VERSION "HIPBNYYYYYYYYYYYYYYYYYYYYYYYYYYYYYYYYYYYYY/4/%%%/4/'%**4YYY///"

NS_ :

BS_:

BU_:

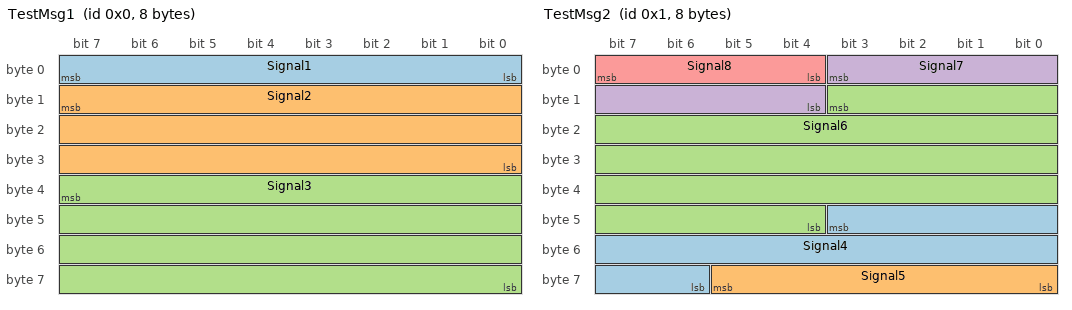
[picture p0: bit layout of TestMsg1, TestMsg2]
BO_ 0 TestMsg1: 8 Vector__XXX
 SG_ Signal1 : 7|8@0- (1,0) [0|0] "" Vector__XXX
 SG_ Signal2 : 15|24@0- (1,0) [0|0] "" Vector__XXX
 SG_ Signal3 : 39|32@0- (1,0) [0|0] "" Vector__XXX

BO_ 1 TestMsg2: 8 Vector__XXX
 SG_ Signal4 : 43|14@0+ (1,0) [0|0] "" Vector__XXX
 SG_ Signal5 : 61|6@0+ (1,0) [0|0] "" Vector__XXX
 SG_ Signal6 : 11|32@0- (1,0) [0|0] "" Vector__XXX
 SG_ Signal7 : 3|8@0- (1,0) [0|0] "" Vector__XXX
 SG_ Signal8 : 7|4@0+ (1,0) [0|0] "" Vector__XXX

BO_ 2 TestMsg3: 8 Vector__XXX
 SG_ Signal9 : 7|64@0- (1,0) [0|0] "" Vector__XXX

SIG_VALTYPE_ 0 Signal3 : 1;
SIG_VALTYPE_ 1 Signal6 : 1;
SIG_VALTYPE_ 2 Signal9 : 2;
